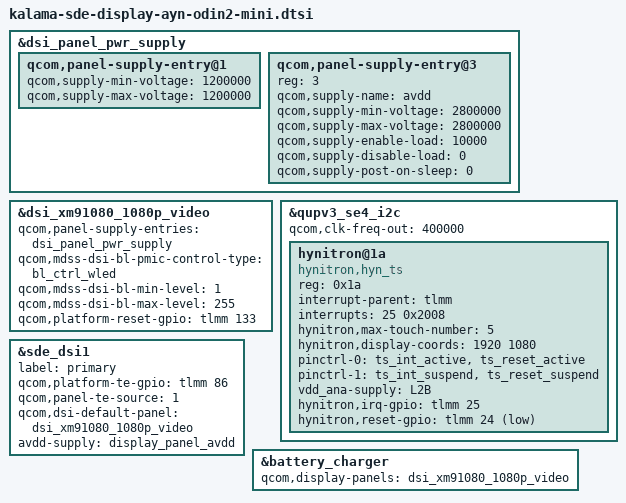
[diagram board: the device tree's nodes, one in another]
#include <dt-bindings/gpio/gpio.h>

#include "kalama-sde-display-moorechip-common.dtsi"
#include "kalama-sde-display-moorechip-hdmi.dtsi"

&dsi_panel_pwr_supply {
	qcom,panel-supply-entry@1 {
		qcom,supply-min-voltage = <1200000>;
		qcom,supply-max-voltage = <1200000>;
	};

	qcom,panel-supply-entry@3 {
		reg = <3>;
		qcom,supply-name = "avdd";
		qcom,supply-min-voltage = <2800000>;
		qcom,supply-max-voltage = <2800000>;
		qcom,supply-enable-load = <10000>;
		qcom,supply-disable-load = <0>;
		qcom,supply-post-on-sleep = <0>;
	};
};

&dsi_xm91080_1080p_video {
	qcom,panel-supply-entries = <&dsi_panel_pwr_supply>;
	qcom,mdss-dsi-bl-pmic-control-type = "bl_ctrl_wled";
	qcom,mdss-dsi-bl-min-level = <1>;
	qcom,mdss-dsi-bl-max-level = <255>;
	qcom,platform-reset-gpio = <&tlmm 133 0>;
};

&qupv3_se4_i2c {
	#address-cells = <1>;
	#size-cells = <0>;

	qcom,clk-freq-out = <400000>;
	status = "okay";

	hynitron@1a {
		compatible = "hynitron,hyn_ts";
		reg = <0x1a>;
		interrupt-parent = <&tlmm>;
		interrupts = <25 0x2008>;
		hynitron,max-touch-number = <5>;
		hynitron,display-coords =  <1920 1080>;
		pinctrl-names = "pmx_ts_active", "pmx_ts_suspend";
		pinctrl-0 = <&ts_int_active &ts_reset_active>;
		pinctrl-1 = <&ts_int_suspend &ts_reset_suspend>;
		vdd_ana-supply = <&L2B>;
		hynitron,irq-gpio = <&tlmm 25 0x02>;
		hynitron,reset-gpio = <&tlmm 24 0x01>;
	};
};

&sde_dsi1 {
	label = "primary";

	qcom,platform-te-gpio = <&tlmm 86 0>;
	qcom,panel-te-source = <1>;

	qcom,dsi-default-panel = <&dsi_xm91080_1080p_video>;

	avdd-supply = <&display_panel_avdd>;
};

&battery_charger {
	qcom,display-panels = <&dsi_xm91080_1080p_video>;
};
